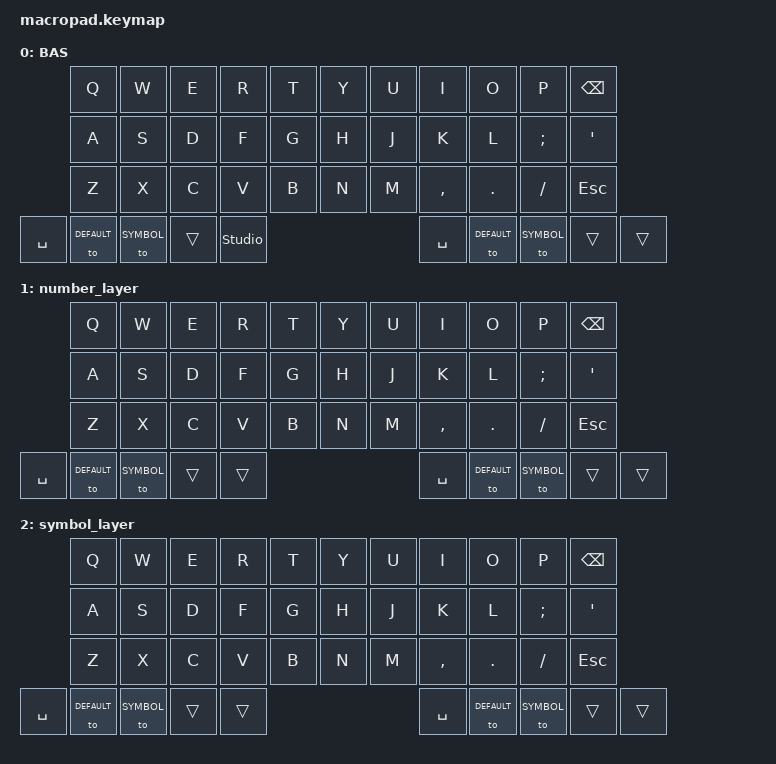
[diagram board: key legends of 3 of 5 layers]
#include <behaviors.dtsi>
#include <dt-bindings/zmk/keys.h>
#include <dt-bindings/zmk/bt.h>

#define DEFAULT 0
#define NUMBER 1
#define SYMBOL 2
#define SETTINGS 3
#define LOCK 4

#define COMBO_TIMEOUT 50

/ {
 
    keymap {
        compatible = "zmk,keymap";

        default_layer {
            display-name = "BAS";
            

            bindings = <
            &kp Q    &kp W   &kp E     &kp R     &kp T                    &kp Y    &kp U  &kp I      &kp O    &kp P     &kp BSPC
            &kp A    &kp S   &kp D     &kp F     &kp G                    &kp H   &kp J  &kp K      &kp L    &kp SEMI  &kp SQT
            &kp Z    &kp X   &kp C     &kp V     &kp B                    &kp N    &kp M  &kp COMMA  &kp DOT  &kp FSLH  &kp ESC
&kp SPACE   &to DEFAULT      &to SYMBOL          &trans &studio_unlock &kp SPACE  &to DEFAULT   &to SYMBOL          &trans &trans
            >;
        };

        number_layer {
            bindings = <
            &kp Q    &kp W   &kp E     &kp R     &kp T                    &kp Y    &kp U  &kp I      &kp O    &kp P     &kp BSPC
            &kp A    &kp S   &kp D     &kp F     &kp G                    &kp H   &kp J  &kp K      &kp L    &kp SEMI  &kp SQT
            &kp Z    &kp X   &kp C     &kp V     &kp B                    &kp N    &kp M  &kp COMMA  &kp DOT  &kp FSLH  &kp ESC
&kp SPACE   &to DEFAULT      &to SYMBOL          &trans &trans &kp SPACE  &to DEFAULT   &to SYMBOL          &trans &trans
            >;
        }; 

        symbol_layer {
            bindings = <
            &kp Q    &kp W   &kp E     &kp R     &kp T                    &kp Y    &kp U  &kp I      &kp O    &kp P     &kp BSPC
            &kp A    &kp S   &kp D     &kp F     &kp G                    &kp H   &kp J  &kp K      &kp L    &kp SEMI  &kp SQT
            &kp Z    &kp X   &kp C     &kp V     &kp B                    &kp N    &kp M  &kp COMMA  &kp DOT  &kp FSLH  &kp ESC
&kp SPACE   &to DEFAULT      &to SYMBOL          &trans &trans &kp SPACE  &to DEFAULT   &to SYMBOL          &trans &trans            >;
        }; 
        
        settings_layer {
            bindings = <
            &bt BT_SEL 0 &bt BT_SEL 1 &bt BT_SEL 2 &bt BT_SEL 3 &bt BT_SEL 4 &bt BT_SEL 0 &bt BT_SEL 1 &bt BT_SEL 2 &bt BT_SEL 3 &bt BT_SEL 4
                            &none        &none        &none        &none        &none  &none        &none        &none        &none        &none 
                            &kp P        &none        &sys_reset   &none        &none  &kp P        &none        &sys_reset   &none        &none
                &bootloader &none                     &none                     &none        &bt BT_CLR  &bootloader &none                     &none                     &none        &bt BT_CLR
            >;
        };

        lock_layer {
            bindings = <
                      &none &none &none &none &none 
                      &none &none &none &none &none 
                      &none &none &none &none &none 
                &none &none       &none       &none       &none
            >;
        };
    };
};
